# STM32L15x register map
File version: 1.0
Registers are 32-bit, read-write, reset 0x0 unless marked. A register's access mark holds for its fields unless they carry their own. Offsets are from the block's base; [hi:lo] are bit positions; {n}, {i} and the like mark numbered series.

## LCD — LCD controller
Base 0x40002400
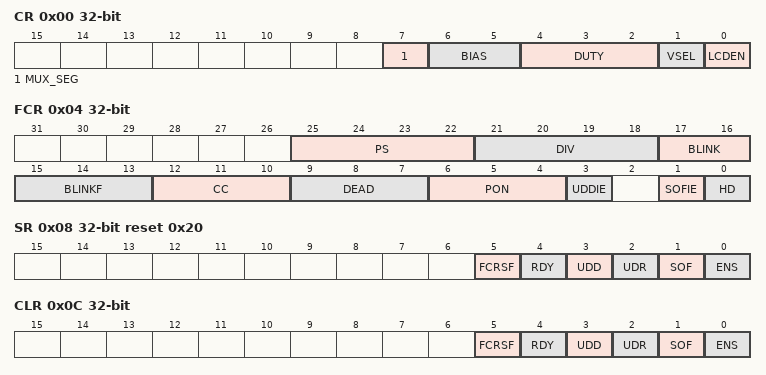
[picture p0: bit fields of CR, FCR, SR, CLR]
0x00 CR — LCD control register
  [7] MUX_SEG, [6:5] BIAS, [4:2] DUTY, [1] VSEL, [0] LCDEN
0x04 FCR — LCD frame control register
  [25:22] PS, [21:18] DIV, [17:16] BLINK, [15:13] BLINKF, [12:10] CC, [9:7] DEAD, [6:4] PON, [3] UDDIE, [1] SOFIE, [0] HD
0x08 SR ro reset 0x20 — LCD status register
  [5] FCRSF, [4] RDY, [3] UDD, [2] UDR, [1] SOF, [0] ENS
0x0C CLR wo — LCD clear register
  [5] FCRSF, [4] RDY, [3] UDD, [2] UDR, [1] SOF, [0] ENS
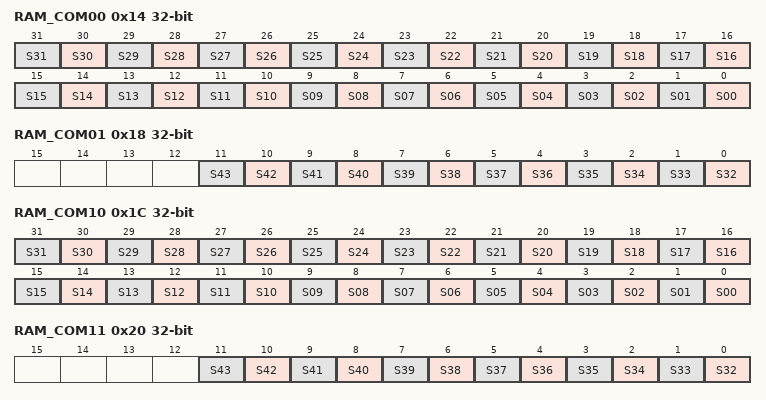
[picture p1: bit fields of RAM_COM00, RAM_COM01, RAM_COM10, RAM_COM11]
0x14 RAM_COM00 — LCD display memory
  [n] S{n:02} (n=0..31)
0x18 RAM_COM01 — LCD display memory
  [n-32] S{n} (n=32..43)
0x1C RAM_COM10 — LCD display memory
  [n] S{n:02} (n=0..31)
0x20 RAM_COM11 — LCD display memory
  [n-32] S{n} (n=32..43)
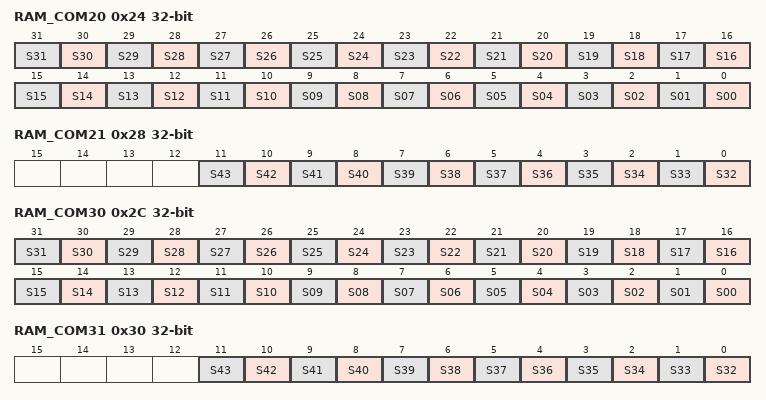
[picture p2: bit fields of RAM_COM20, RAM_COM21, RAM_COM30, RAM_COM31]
0x24 RAM_COM20 — LCD display memory
  [n] S{n:02} (n=0..31)
0x28 RAM_COM21 — LCD display memory
  [n-32] S{n} (n=32..43)
0x2C RAM_COM30 — LCD display memory
  [n] S{n:02} (n=0..31)
0x30 RAM_COM31 — LCD display memory
  [n-32] S{n} (n=32..43)
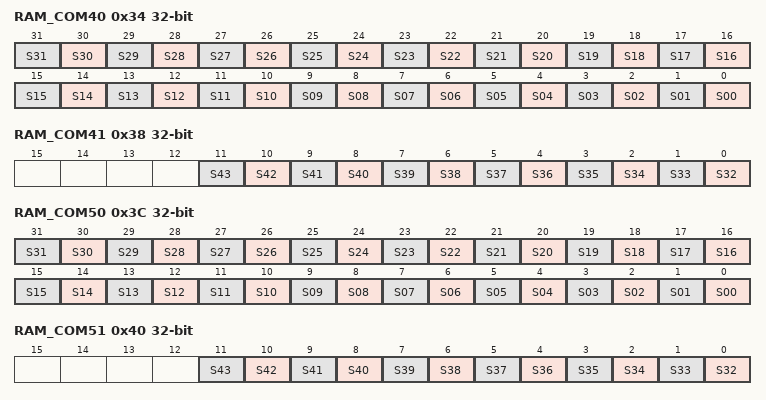
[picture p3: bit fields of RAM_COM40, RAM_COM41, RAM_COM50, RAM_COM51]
0x34 RAM_COM40 — LCD display memory
  [n] S{n:02} (n=0..31)
0x38 RAM_COM41 — LCD display memory
  [n-32] S{n} (n=32..43)
0x3C RAM_COM50 — LCD display memory
  [n] S{n:02} (n=0..31)
0x40 RAM_COM51 — LCD display memory
  [n-32] S{n} (n=32..43)
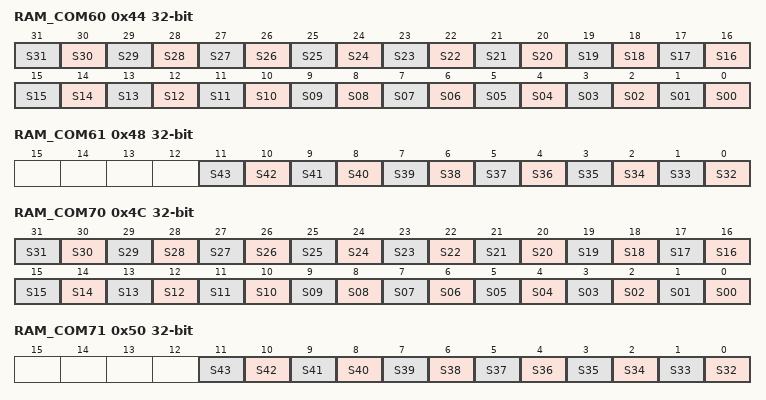
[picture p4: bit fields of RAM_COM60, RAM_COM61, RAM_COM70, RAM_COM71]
0x44 RAM_COM60 — LCD display memory
  [n] S{n:02} (n=0..31)
0x48 RAM_COM61 — LCD display memory
  [n-32] S{n} (n=32..43)
0x4C RAM_COM70 — LCD display memory
  [n] S{n:02} (n=0..31)
0x50 RAM_COM71 — LCD display memory
  [n-32] S{n} (n=32..43)

## DBG — Debug support
Base 0xE0042000
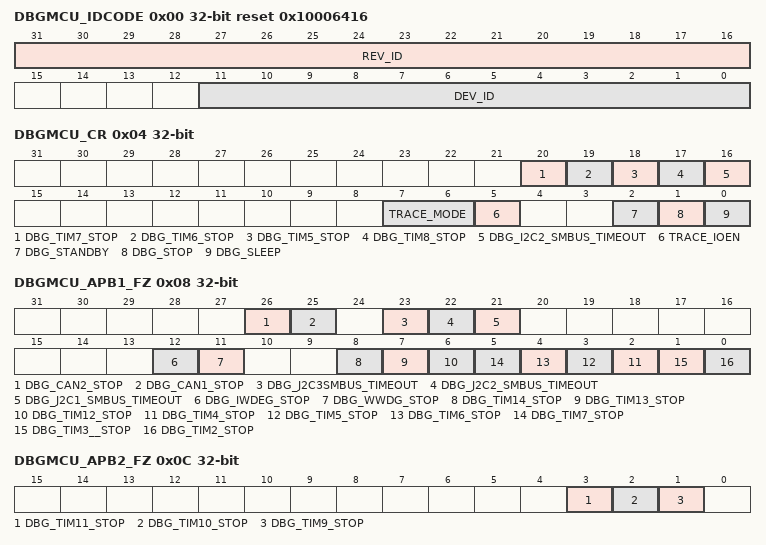
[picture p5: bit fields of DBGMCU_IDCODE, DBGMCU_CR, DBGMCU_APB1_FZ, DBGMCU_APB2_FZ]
0x00 DBGMCU_IDCODE ro reset 0x10006416 — IDCODE
  [31:16] REV_ID, [11:0] DEV_ID
0x04 DBGMCU_CR — Control Register
  [20] DBG_TIM7_STOP, [19] DBG_TIM6_STOP, [18] DBG_TIM5_STOP, [17] DBG_TIM8_STOP, [16] DBG_I2C2_SMBUS_TIMEOUT, [7:6] TRACE_MODE, [5] TRACE_IOEN, [2] DBG_STANDBY, [1] DBG_STOP, [0] DBG_SLEEP
0x08 DBGMCU_APB1_FZ — Debug MCU APB1 Freeze registe
  [26] DBG_CAN2_STOP, [25] DBG_CAN1_STOP, [23] DBG_J2C3SMBUS_TIMEOUT, [22] DBG_J2C2_SMBUS_TIMEOUT, [21] DBG_J2C1_SMBUS_TIMEOUT, [12] DBG_IWDEG_STOP, [11] DBG_WWDG_STOP, [8] DBG_TIM14_STOP, [7] DBG_TIM13_STOP, [6] DBG_TIM12_STOP, [n-2] DBG_TIM{n}_STOP (n=4..7), [1] DBG_TIM3__STOP, [0] DBG_TIM2_STOP
0x0C DBGMCU_APB2_FZ — Debug MCU APB2 Freeze registe
  [3] DBG_TIM11_STOP — no info available
  [2] DBG_TIM10_STOP — no info available
  [1] DBG_TIM9_STOP — no info available

## EXTI — External interrupt/event controller
Base 0x40010400
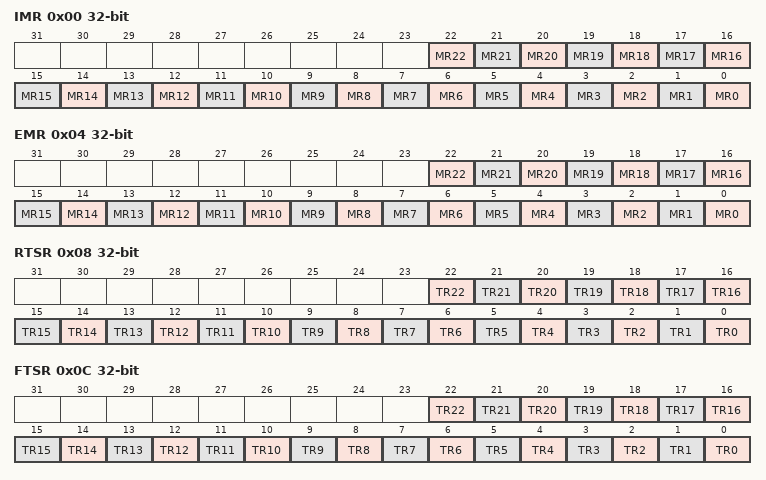
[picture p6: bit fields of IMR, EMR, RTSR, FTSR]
0x00 IMR — Interrupt mask register
  [n] MR{n} (n=0..22) — Event mask on line {n}
0x04 EMR — Event mask register
  [n] MR{n} (n=0..22) — Event mask on line x
0x08 RTSR — Rising trigger selection register
  [n] TR{n} (n=0..22) — Rising trigger event configuration bit of line x
0x0C FTSR — Falling trigger selection register
  [n] TR{n} (n=0..22) — Falling trigger event configuration bit of line x
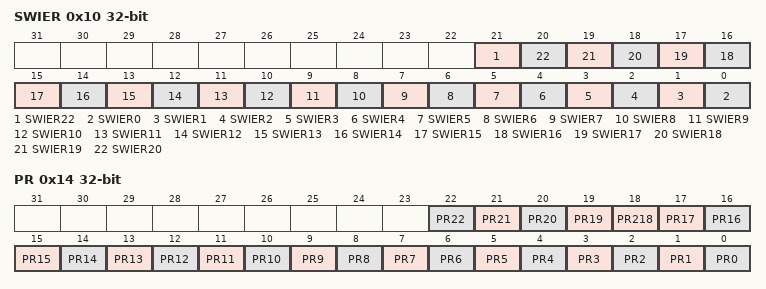
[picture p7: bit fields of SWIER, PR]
0x10 SWIER — Software interrupt event register
  [21] SWIER22 — Software Interrupt on line x
  [n] SWIER{n} (n=0..20) — Software Interrupt on line x
0x14 PR — Pending register
  [n] PR{n} (n=19..22) — Pending bit x
  [18] PR218 — Pending bit x
  [n] PR{n} (n=0..17) — Pending bit x

## RI — Routing interface (RI)
Base 0x40007C04
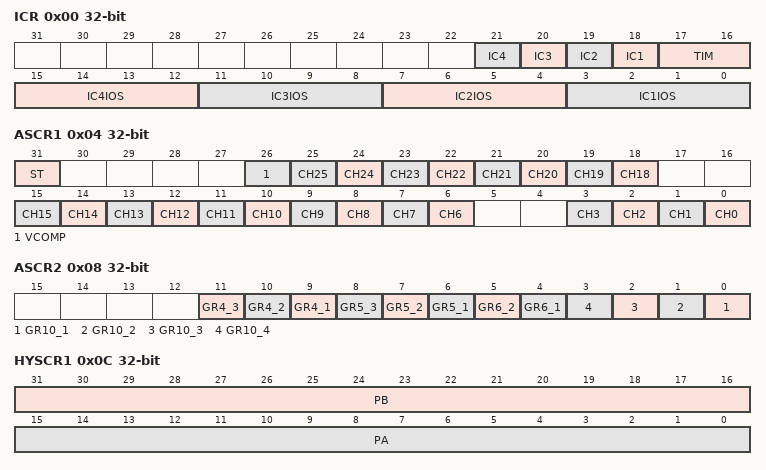
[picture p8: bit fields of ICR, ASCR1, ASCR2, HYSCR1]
0x00 ICR — RI input capture register
  [n+17] IC{n} (n=1..4), [17:16] TIM, [4n-1:4n-4] IC{n}IOS (n=1..4)
0x04 ASCR1 — RI analog switches control register 1
  [31] ST, [26] VCOMP, [n] CH{n} (n=18..25), [n] CH{n} (n=6..15), [n] CH{n} (n=0..3)
0x08 ASCR2 — RI analog switches control register 2
  [11] GR4_3, [10] GR4_2, [9] GR4_1, [8] GR5_3, [7] GR5_2, [6] GR5_1, [5] GR6_2, [4] GR6_1, [n-1] GR10_{n} (n=1..4)
0x0C HYSCR1 — RI hysteresis control register 1
  [31:16] PB, [15:0] PA
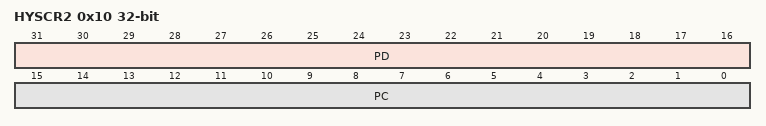
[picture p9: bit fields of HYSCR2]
0x10 HYSCR2 — RI hysteresis control register 2
  [31:16] PD, [15:0] PC
0x14 HYSCR3 — RI hysteresis control register 3
  [15:0] PE
